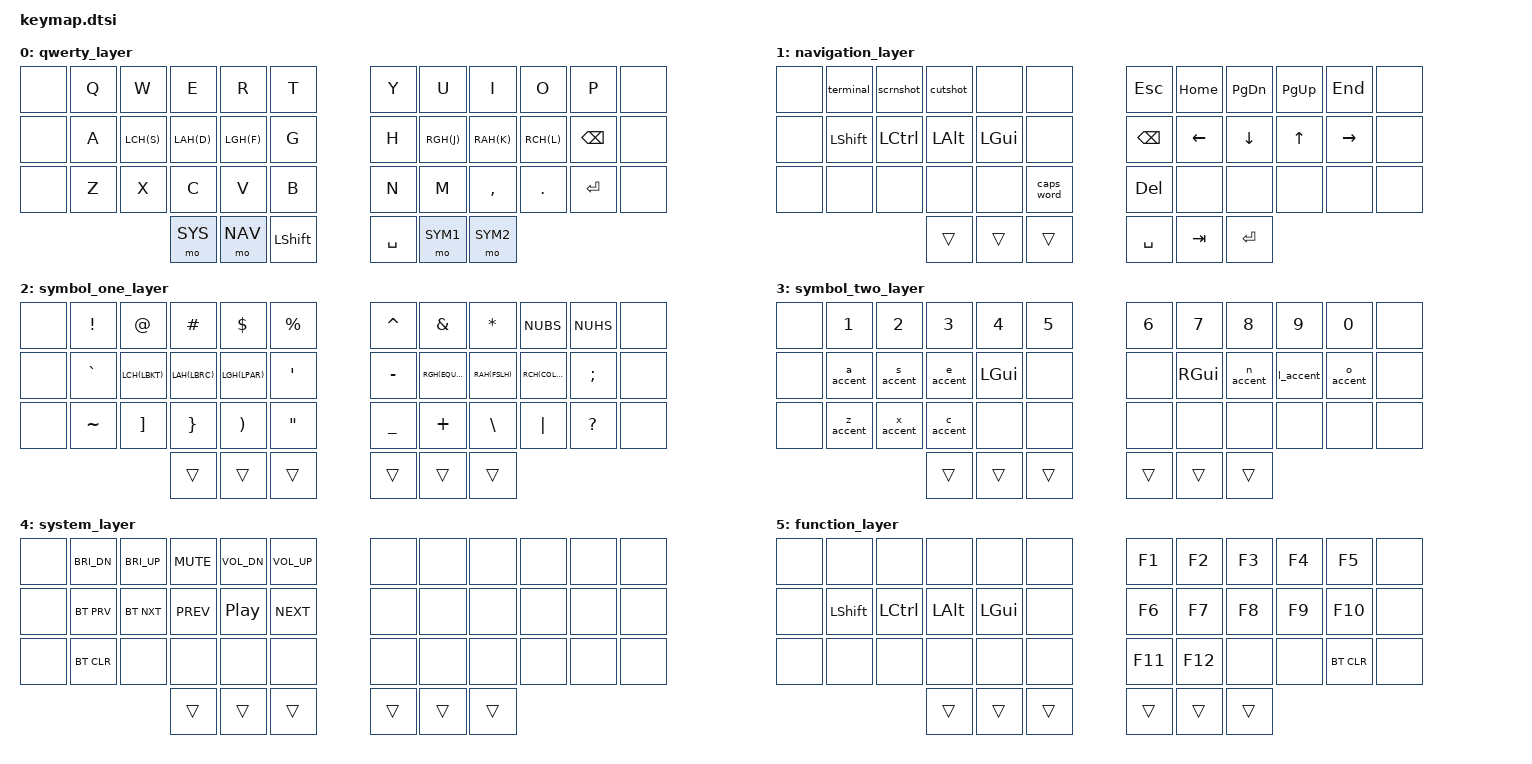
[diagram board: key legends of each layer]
#define FUNLT(k1) &lt FUN k1

#define LSH(k1) &hm LSHIFT k1
#define LCH(k1) &hm LCTRL k1
#define LAH(k1) &hm LALT k1
#define LGH(k1) &hm LGUI k1

#define RSH(k1) &hm RSHIFT k1
#define RCH(k1) &hm RCTRL k1
#define RAH(k1) &hm RALT k1
#define RGH(k1) &hm RGUI k1

#define BRI_UP &kp C_BRI_UP
#define BRI_DN &kp C_BRI_DN
#define VOL_UP &kp C_VOL_UP
#define VOL_DN &kp C_VOL_DN
#define MUTE   &kp K_MUTE

/ {
    keymap {
        compatible = "zmk,keymap";
        qwerty_layer {
            bindings = <
            //           ╭──────────┬──────────┬──────────┬──────────┬──────────╮   ╭──────────┬──────────┬──────────┬──────────┬──────────╮
            //           │  Q       │  W       │  E       │  R       │  T       │   │  Y       │  U       │  I       │  O       │  P       │
                &none      &kp Q      &kp W      &kp E      &kp R      &kp T          &kp Y      &kp U      &kp I      &kp O      &kp P      &none
            //           ├──────────┼──────────┼──────────┼──────────┼──────────┤   ├──────────┼──────────┼──────────┼──────────┼──────────┤
            //           │  A       │  S       │  D       │  F       │  G       │   │  H       │  J       │  K       │  L       │  BSPC    │
                &none      &kp A      LCH(S)     LAH(D)     LGH(F)     &kp G          &kp H      RGH(J)     RAH(K)     RCH(L)     &kp BSPC   &none
            //           ├──────────┼──────────┼──────────┼──────────┼──────────┤   ├──────────┼o──────────┼──────────┼──────────┼──────────┤
            //           │  Z       │  X       │  C       │  V       │  B       │   │  N       │  M       │  COMMA   │  DOT     │  ENTER   │
                &none      &kp Z      &kp X      &kp C      &kp V      &kp B          &kp N      &kp M      &kp COMMA  &kp DOT    &kp RET    &none
            //           ╰──────────┴──────────┼──────────┼──────────┼──────────┤   ├──────────┼──────────┼──────────┼──────────┴──────────╯
            //                                 │          │          │          │   │          │          │          │
                                                 &mo SYS    &mo NAV    &kp LSHIFT     &kp SPACE  &mo SYM1   &mo SYM2
            //                                 ╰──────────┴──────────┴──────────╯   ╰──────────┴──────────┴──────────╯
            >;
        };
        navigation_layer {
            bindings = <
            //           ╭──────────┬──────────┬──────────┬──────────┬──────────╮   ╭──────────┬──────────┬──────────┬──────────┬──────────╮
            //           │          │          │          │          │          │   │          │          │          │          │          │
                &none      &terminal  &scrnshot  &cutshot   &none      &none          &kp ESC    &kp HOME   &kp PG_DN  &kp PG_UP  &kp END    &none
            //           ├──────────┼──────────┼──────────┼──────────┼──────────┤   ├──────────┼──────────┼──────────┼──────────┼──────────┤
            //           │          │          │          │          │          │   │          │          │          │          │          │
                &none      &kp LSHIFT &kp LCTRL  &kp LALT   &kp LGUI   &none          &kp BSPC   &kp LEFT   &kp DOWN   &kp UP     &kp RIGHT  &none
            //           ├──────────┼──────────┼──────────┼──────────┼──────────┤   ├──────────┼──────────┼──────────┼──────────┼──────────┤
            //           │          │          │          │          │          │   │          │          │          │          │          │
                &none      &none      &none      &none      &none      &caps_word     &kp DEL    &none      &none      &none      &none      &none 
            //           ╰──────────┴──────────┼──────────┼──────────┼──────────┤   ├──────────┼──────────┼──────────┼──────────┴──────────╯
            //                                 │          │          │          │   │          │          │          │
                                                 &trans     &trans     &trans         &kp SPACE  &kp TAB    &kp RET
            //                                 ╰──────────┴──────────┴──────────╯   ╰──────────┴──────────┴──────────╯
            >;
        };
        symbol_one_layer {
            bindings = <
            //           ╭──────────┬──────────┬──────────┬──────────┬──────────╮   ╭──────────┬──────────┬──────────┬──────────┬──────────╮
            //           │  !       │  @       │  #       │  $       │  %       │   │  ^       │  &       │  *       │  §       │          │
                &none      &kp EXCL   &kp AT     &kp HASH   &kp DLLR   &kp PRCNT      &kp CARET  &kp AMPS   &kp ASTRK  &kp NUBS   &kp NUHS   &none
            //           ├──────────┼──────────┼──────────┼──────────┼──────────┤   ├──────────┼──────────┼──────────┼──────────┼──────────┤
            //           │  `       │  [       │  {       │  (       │  '       │   │  -       │  =       │  /       │  :       │  ;       │
                &none      &kp GRAVE  LCH(LBKT)  LAH(LBRC)  LGH(LPAR)  &kp SQT        &kp MINUS  RGH(EQUAL) RAH(FSLH)  RCH(COLON) &kp SEMI   &none
            //           ├──────────┼──────────┼──────────┼──────────┼──────────┤   ├──────────┼──────────┼──────────┼──────────┼──────────┤
            //           │  ~       │  ]       │  }       │  )       │  "       │   │  _       │  +       │  \       │  |       │  ?       │
                &none      &kp TILDE  &kp RBKT   &kp RBRC   &kp RPAR   &kp DQT        &kp UNDER  &kp PLUS   &kp BSLH   &kp PIPE   &kp QMARK  &none
            //           ╰──────────┴──────────┼──────────┼──────────┼──────────┤   ├──────────┼──────────┼──────────┼──────────┴──────────╯
            //                                 │          │          │          │   │          │          │          │
                                                 &trans     &trans     &trans         &trans     &trans     &trans
            //                                 ╰──────────┴──────────┴──────────╯   ╰──────────┴──────────┴──────────╯
            >;
        };
        symbol_two_layer {
            bindings = <
            //           ╭──────────┬──────────┬──────────┬──────────┬──────────╮   ╭──────────┬──────────┬──────────┬──────────┬──────────╮
            //           │  1       │  2       │  3       │  4       │  5       │   │  6       │  7       │  8       │  9       │  0       │
                &none      &kp N1     &kp N2     &kp N3     &kp N4     &kp N5         &kp N6     &kp N7     &kp N8     &kp N9     &kp N0     &none
            //           ├──────────┼──────────┼──────────┼──────────┼──────────┤   ├──────────┼──────────┼──────────┼──────────┼──────────┤
            //           │          │          │          │          │          │   │          │          │          │          │          │
                &none      &a_accent  &s_accent  &e_accent  &kp LGUI   &none          &none      &kp RGUI   &n_accent  &l_accent  &o_accent  &none
            //           ├──────────┼──────────┼──────────┼──────────┼──────────┤   ├──────────┼──────────┼──────────┼──────────┼──────────┤
            //           │          │          │          │          │          │   │          │          │          │          │          │
                &none      &z_accent  &x_accent  &c_accent  &none      &none          &none      &none      &none      &none      &none      &none
            //           ╰──────────┴──────────┼──────────┼──────────┼──────────┤   ├──────────┼──────────┼──────────┼──────────┴──────────╯
            //                                 │          │          │          │   │          │          │          │
                                                 &trans     &trans     &trans         &trans     &trans     &trans
            //                                 ╰──────────┴──────────┴──────────╯   ╰──────────┴──────────┴──────────╯
            >;
        };
        system_layer {
            bindings = <
            //           ╭──────────┬──────────┬──────────┬──────────┬──────────╮   ╭──────────┬──────────┬──────────┬──────────┬──────────╮
            //           │          │          │          │          │          │   │          │          │          │          │          │
                &none      BRI_DN     BRI_UP     MUTE       VOL_DN     VOL_UP         &none      &none      &none      &none      &none      &none
            //           ├──────────┼──────────┼──────────┼──────────┼──────────┤   ├──────────┼──────────┼──────────┼──────────┼──────────┤
            //           │          │          │          │          │          │   │          │          │          │          │          │
                &none      &bt BT_PRV &bt BT_NXT &kp C_PREV &kp C_PP   &kp C_NEXT     &none      &none      &none      &none      &none      &none
            //           ├──────────┼──────────┼──────────┼──────────┼──────────┤   ├──────────┼──────────┼──────────┼──────────┼──────────┤
            //           │          │          │          │          │          │   │          │          │          │          │          │
                &none      &bt BT_CLR &none      &none      &none      &none          &none      &none      &none      &none      &none      &none
            //           ╰──────────┴──────────┼──────────┼──────────┼──────────┤   ├──────────┼──────────┼──────────┼──────────┴──────────╯
            //                                 │          │          │          │   │          │          │          │
                                                 &trans     &trans     &trans         &trans     &trans     &trans
            //                                 ╰──────────┴──────────┴──────────╯   ╰──────────┴──────────┴──────────╯
            >;
        };
        function_layer {
            bindings = <
            //           ╭──────────┬──────────┬──────────┬──────────┬──────────╮   ╭──────────┬──────────┬──────────┬──────────┬──────────╮
            //           │          │          │          │          │          │   │  F1      │  F2      │  F3      │  F4      │  F5      │
                &none      &none      &none      &none      &none      &none          &kp F1     &kp F2     &kp F3     &kp F4     &kp F5     &none
            //           ├──────────┼──────────┼──────────┼──────────┼──────────┤   ├──────────┼──────────┼──────────┼──────────┼──────────┤
            //           │          │          │          │          │          │   │  F6      │  F7      │  F8      │  F9      │  F10     │
                &none      &kp LSHIFT &kp LCTRL  &kp LALT   &kp LGUI   &none          &kp F6     &kp F7     &kp F8     &kp F9     &kp F10    &none
            //           ├──────────┼──────────┼──────────┼──────────┼──────────┤   ├──────────┼──────────┼──────────┼──────────┼──────────┤
            //           │          │          │          │          │          │   │   F11    │  F12     │          │          │          │
                &none      &none      &none      &none      &none      &none          &kp F11    &kp F12    &none      &none      &bt BT_CLR &none
            //           ╰──────────┴──────────┼──────────┼──────────┼──────────┤   ├──────────┼──────────┼──────────┼──────────┴──────────╯
            //                                 │          │          │          │   │          │          │          │
                                                 &trans     &trans     &trans         &trans     &trans     &trans
            //                                 ╰──────────┴──────────┴──────────╯   ╰──────────┴──────────┴──────────╯
            >;
        };
    };
};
